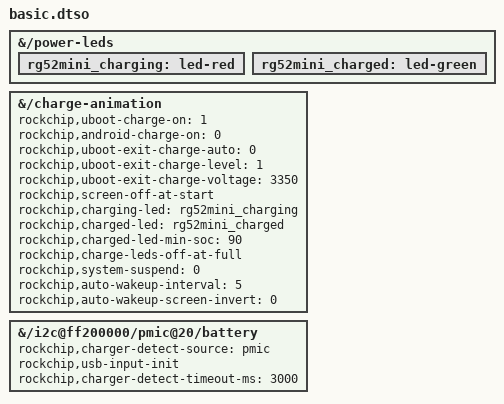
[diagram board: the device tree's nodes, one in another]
// SPDX-License-Identifier: GPL-2.0+
/* RG52 Mini screen-off charging; preserve its own rails and battery data. */
/dts-v1/;
/plugin/;
/ {
	fragment@0 {
		target-path = "/power-leds";
		__overlay__ {
			/* Reuse the RG52 Mini's existing LED GPIOs and pin configuration. */
			rg52mini_charging: led-red {};
			rg52mini_charged: led-green {};
		};
	};

	fragment@1 {
		target-path = "/charge-animation";
		__overlay__ {
			status = "okay";
			rockchip,uboot-charge-on = <1>;
			rockchip,android-charge-on = <0>;
			rockchip,uboot-exit-charge-auto = <0>;
			rockchip,uboot-exit-charge-level = <1>;
			rockchip,uboot-exit-charge-voltage = <3350>;
			rockchip,screen-off-at-start;
			rockchip,charging-led = <&rg52mini_charging>;
			rockchip,charged-led = <&rg52mini_charged>;
			rockchip,charged-led-min-soc = <90>;
			rockchip,charge-leds-off-at-full;
			rockchip,system-suspend = <0>;
			rockchip,auto-wakeup-interval = <5>;
			rockchip,auto-wakeup-screen-invert = <0>;
		};
	};

	fragment@2 {
		target-path = "/i2c@ff200000/pmic@20/battery";
		__overlay__ {
			/* Use RK817 insertion status instead of the inherited DC GPIO. */
			rockchip,charger-detect-source = "pmic";
			rockchip,usb-input-init;
			rockchip,charger-detect-timeout-ms = <3000>;
		};
	};
};
